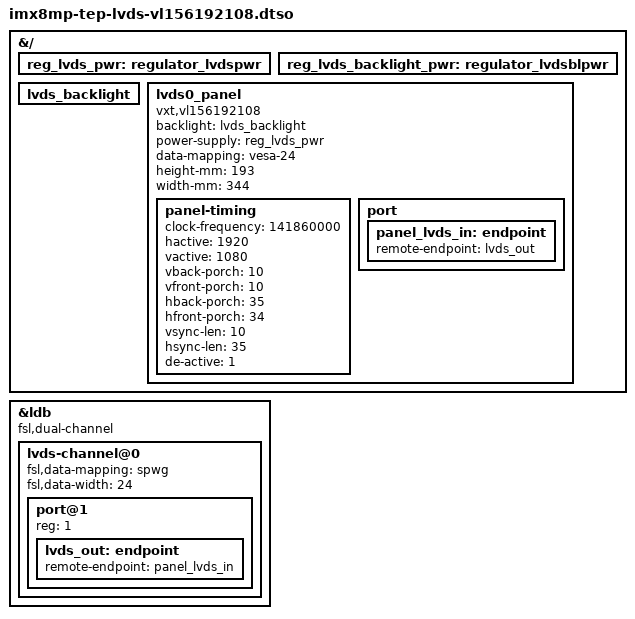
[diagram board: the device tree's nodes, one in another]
// SPDX-License-Identifier: (GPL-2.0 OR MIT)
/*
 * Copyright 2020 TechNexion Ltd.
 *
 * Author: Ray Chang <ray.chang@technexion.com>
 *
 */

/dts-v1/;
/plugin/;

#include <dt-bindings/interrupt-controller/irq.h>
#include <dt-bindings/gpio/gpio.h>

&{/} {
	reg_lvds_pwr: regulator_lvdspwr {
		status = "okay";
	};

	reg_lvds_backlight_pwr: regulator_lvdsblpwr {
		status = "okay";
	};

	lvds_backlight: lvds_backlight {
		status = "okay";
	};

	lvds0_panel {
		compatible = "vxt,vl156192108", "panel-lvds";
		backlight = <&lvds_backlight>;
		power-supply = <&reg_lvds_pwr>;

		data-mapping = "vesa-24";
		height-mm = <193>;
		width-mm = <344>;

		panel-timing {
			clock-frequency = <141860000>;
			hactive = <1920>;
			vactive = <1080>;
			vback-porch = <10>;
			vfront-porch = <10>;
			hback-porch = <35>;
			hfront-porch = <34>;
			vsync-len = <10>;
			hsync-len = <35>;
			de-active = <1>;
		};

		port {
			panel_lvds_in: endpoint {
				remote-endpoint = <&lvds_out>;
			};
		};
	};
};

&ldb {
	status = "okay";
	fsl,dual-channel;
	lvds-channel@0 {
		#address-cells = <1>;
		#size-cells = <0>;
		fsl,data-mapping = "spwg";
		fsl,data-width = <24>;
		status = "okay";

		port@1 {
			reg = <1>;

			lvds_out: endpoint {
				remote-endpoint = <&panel_lvds_in>;
			};
		};
	};
};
